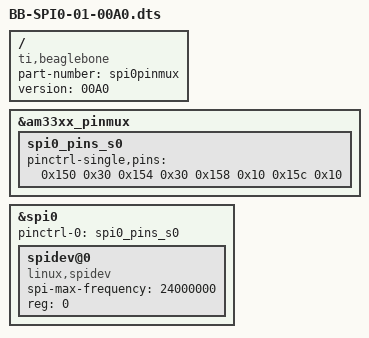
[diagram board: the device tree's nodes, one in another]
/* This Source Code Form is subject to the terms of the Mozilla Public
 * License, v. 2.0. If a copy of the MPL was not distributed with this
 * file, You can obtain one at http://mozilla.org/MPL/2.0/. */
/dts-v1/;
/plugin/;

/* SPI1 */
/* D1 output and D0 input */

/ {
    compatible = "ti,beaglebone", "ti,beaglebone-black";

    part-number = "spi0pinmux";
    version = "00A0";

    fragment@0 {
        target = <&am33xx_pinmux>;
        __overlay__ {
            spi0_pins_s0: spi0_pins_s0 {
                pinctrl-single,pins = <
                    0x150 0x30 /* P9_22 = spi0_sclk, INPUT_PULLUP | MODE0 */
                    0x154 0x30 /* P9_21 = spi0_d0, INPUT_PULLUP | MODE0 */
                    0x158 0x10 /* P9_18 = spi0_d1, OUTPUT_PULLUP | MODE0 */
                    0x15c 0x10 /* P9_17 = spi0_cs0, OUTPUT_PULLUP | MODE0 */
                >;
            };
        };
    };

    fragment@1 {
        target = <&spi0>;
        __overlay__ {
            #address-cells = <1>;
            #size-cells = <0>;

            status = "okay";
            pinctrl-names = "default";
            pinctrl-0 = <&spi0_pins_s0>;

            spidev@0 {
                spi-max-frequency = <24000000>;
                reg = <0>;
                compatible = "linux,spidev";
            };
        };
    };
};
